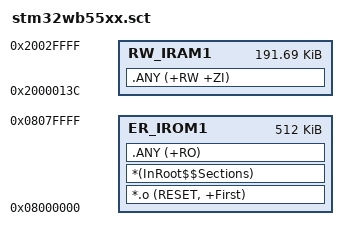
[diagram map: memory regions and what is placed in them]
#! armcc -E
;;;;;;;;;;;;;;;;;;;;;;;;;;;;;;;;;;;;;;;;;;;;;;;;;;;;;;;;;;;;;;;;;;;;;;;;;;;;;;;;
; mbed Microcontroller Library
; Copyright (c) 2006-2013 ARM Limited
;
; Licensed under the Apache License, Version 2.0 (the "License");
; you may not use this file except in compliance with the License.
; You may obtain a copy of the License at
;
;     http://www.apache.org/licenses/LICENSE-2.0
;
; Unless required by applicable law or agreed to in writing, software
; distributed under the License is distributed on an "AS IS" BASIS,
; WITHOUT WARRANTIES OR CONDITIONS OF ANY KIND, either express or implied.
; See the License for the specific language governing permissions and
; limitations under the License.
;;;;;;;;;;;;;;;;;;;;;;;;;;;;;;;;;;;;;;;;;;;;;;;;;;;;;;;;;;;;;;;;;;;;;;;;;;;;;;;;
#if !defined(MBED_APP_START)
  #define MBED_APP_START 0x08000000
#endif

#if !defined(MBED_APP_SIZE)
; 512KB FLASH
  #define MBED_APP_SIZE 0x80000
#endif

LR_IROM1 MBED_APP_START MBED_APP_SIZE  {    ; load region size_region

  ER_IROM1 MBED_APP_START MBED_APP_SIZE  {  ; load address = execution address
   *.o (RESET, +First)
   *(InRoot$$Sections)
   .ANY (+RO)
  }

  ; SRAM1 192KB (0x30000)
  ; Total: 79 vectors = 316 bytes (0x13C) to be reserved in RAM
  RW_IRAM1 (0x20000000+0x13C) (0x30000-0x13C)  {  ; RW data
   .ANY (+RW +ZI)
  }

}

